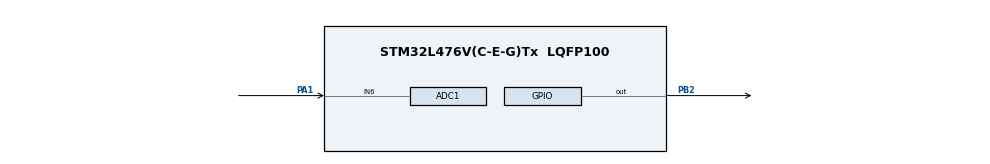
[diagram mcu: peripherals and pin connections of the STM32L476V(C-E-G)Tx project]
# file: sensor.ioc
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ADC1.Channel-0\#ChannelRegularConversion=ADC_CHANNEL_6
ADC1.ContinuousConvMode=ENABLE
ADC1.NbrOfConversionFlag=1
ADC1.OffsetNumber-0\#ChannelRegularConversion=ADC_OFFSET_NONE
ADC1.Overrun=ADC_OVR_DATA_OVERWRITTEN
ADC1.Rank-0\#ChannelRegularConversion=1
ADC1.SamplingTime-0\#ChannelRegularConversion=ADC_SAMPLETIME_47CYCLES_5
ADC1.master=1
Mcu.Family=STM32L4
Mcu.Name=STM32L476V(C-E-G)Tx
Mcu.Package=LQFP100
NVIC.PriorityGroup=NVIC_PRIORITYGROUP_4
PA1.Signal=ADCx_IN6
PB2.Signal=GPIO_Output
ProjectManager.HeapSize=0x200
ProjectManager.StackSize=0x400
ProjectManager.TargetToolchain=STM32CubeIDE
RCC.ADCFreq_Value=32000000
RCC.HSE_VALUE=8000000
RCC.HSI_VALUE=16000000
RCC.LSE_VALUE=32768
RCC.MSI_VALUE=4000000
RCC.PLLSAI1N=16
RCC.USBFreq_Value=32000000
RCC.VCOOutputFreq_Value=32000000
SH.ADCx_IN6.0=ADC1_IN6,IN6-Single-Ended
board=custom

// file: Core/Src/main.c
/* USER CODE BEGIN Header */
/**
  ******************************************************************************
  * @file           : main.c
  * @brief          : Sound Sensor Toggle Project
  ******************************************************************************
  */
/* USER CODE END Header */

#include "main.h"
#include <stdint.h>

ADC_HandleTypeDef hadc1; // Global declaration so main can see it

/* USER CODE BEGIN PV */
uint32_t sound_level = 0;
uint32_t threshold = 1000; // Adjust this if the LED toggles too easily
/* USER CODE END PV */

void SystemClock_Config(void);
static void MX_GPIO_Init(void);
static void MX_ADC1_Init(void);

int main(void)
{
  /* MCU Configuration */
  HAL_Init();
  SystemClock_Config();

  /* Initialize all configured peripherals */
  MX_GPIO_Init();
  MX_ADC1_Init();

  /* USER CODE BEGIN 2 */
  // Calibrate and Start the ADC
  HAL_ADCEx_Calibration_Start(&hadc1, ADC_SINGLE_ENDED);
  HAL_ADC_Start(&hadc1);
  /* USER CODE END 2 */

  /* Infinite loop */
  while (1)
  {
    /* Check for ADC Conversion */
    if (HAL_ADC_PollForConversion(&hadc1, 10) == HAL_OK)
    {
        sound_level = HAL_ADC_GetValue(&hadc1);

        // Toggle LED if sound level is above threshold
        if (sound_level > threshold)
        {
            HAL_GPIO_TogglePin(GPIOB, GPIO_PIN_2);
            HAL_Delay(250); // Pause to avoid double-triggers
        }
    }
  }
}

void SystemClock_Config(void)
{
  RCC_OscInitTypeDef RCC_OscInitStruct = {0};
  RCC_ClkInitTypeDef RCC_ClkInitStruct = {0};

  if (HAL_PWREx_ControlVoltageScaling(PWR_REGULATOR_VOLTAGE_SCALE1) != HAL_OK)
  {
    Error_Handler();
  }

  RCC_OscInitStruct.OscillatorType = RCC_OSCILLATORTYPE_MSI;
  RCC_OscInitStruct.MSIState = RCC_MSI_ON;
  RCC_OscInitStruct.MSICalibrationValue = 0;
  RCC_OscInitStruct.MSIClockRange = RCC_MSIRANGE_6;
  RCC_OscInitStruct.PLL.PLLState = RCC_PLL_NONE;
  if (HAL_RCC_OscConfig(&RCC_OscInitStruct) != HAL_OK)
  {
    Error_Handler();
  }

  RCC_ClkInitStruct.ClockType = RCC_CLOCKTYPE_HCLK|RCC_CLOCKTYPE_SYSCLK
                              |RCC_CLOCKTYPE_PCLK1|RCC_CLOCKTYPE_PCLK2;
  RCC_ClkInitStruct.SYSCLKSource = RCC_SYSCLKSOURCE_MSI;
  RCC_ClkInitStruct.AHBCLKDivider = RCC_SYSCLK_DIV1;
  RCC_ClkInitStruct.APB1CLKDivider = RCC_HCLK_DIV1;
  RCC_ClkInitStruct.APB2CLKDivider = RCC_HCLK_DIV1;

  if (HAL_RCC_ClockConfig(&RCC_ClkInitStruct, FLASH_LATENCY_0) != HAL_OK)
  {
    Error_Handler();
  }
}

static void MX_ADC1_Init(void)
{
  ADC_ChannelConfTypeDef sConfig = {0};

  hadc1.Instance = ADC1;
  hadc1.Init.ClockPrescaler = ADC_CLOCK_ASYNC_DIV1;
  hadc1.Init.Resolution = ADC_RESOLUTION_12B;
  hadc1.Init.DataAlign = ADC_DATAALIGN_RIGHT;
  hadc1.Init.ScanConvMode = ADC_SCAN_DISABLE;
  hadc1.Init.EOCSelection = ADC_EOC_SINGLE_CONV;
  hadc1.Init.ContinuousConvMode = ENABLE;
  hadc1.Init.NbrOfConversion = 1;
  hadc1.Init.ExternalTrigConv = ADC_SOFTWARE_START;
  hadc1.Init.Overrun = ADC_OVR_DATA_OVERWRITTEN;
  if (HAL_ADC_Init(&hadc1) != HAL_OK)
  {
    Error_Handler();
  }

  sConfig.Channel = ADC_CHANNEL_6; // This is Pin PA1
  sConfig.Rank = ADC_REGULAR_RANK_1;
  sConfig.SamplingTime = ADC_SAMPLETIME_47CYCLES_5;
  if (HAL_ADC_ConfigChannel(&hadc1, &sConfig) != HAL_OK)
  {
    Error_Handler();
  }
}

static void MX_GPIO_Init(void)
{
  GPIO_InitTypeDef GPIO_InitStruct = {0};

  __HAL_RCC_GPIOA_CLK_ENABLE();
  __HAL_RCC_GPIOB_CLK_ENABLE();

  HAL_GPIO_WritePin(GPIOB, GPIO_PIN_2, GPIO_PIN_RESET);

  GPIO_InitStruct.Pin = GPIO_PIN_2;
  GPIO_InitStruct.Mode = GPIO_MODE_OUTPUT_PP;
  GPIO_InitStruct.Pull = GPIO_NOPULL;
  GPIO_InitStruct.Speed = GPIO_SPEED_FREQ_LOW;
  HAL_GPIO_Init(GPIOB, &GPIO_InitStruct);
}

void Error_Handler(void)
{
  __disable_irq();
  while (1) {}
}
